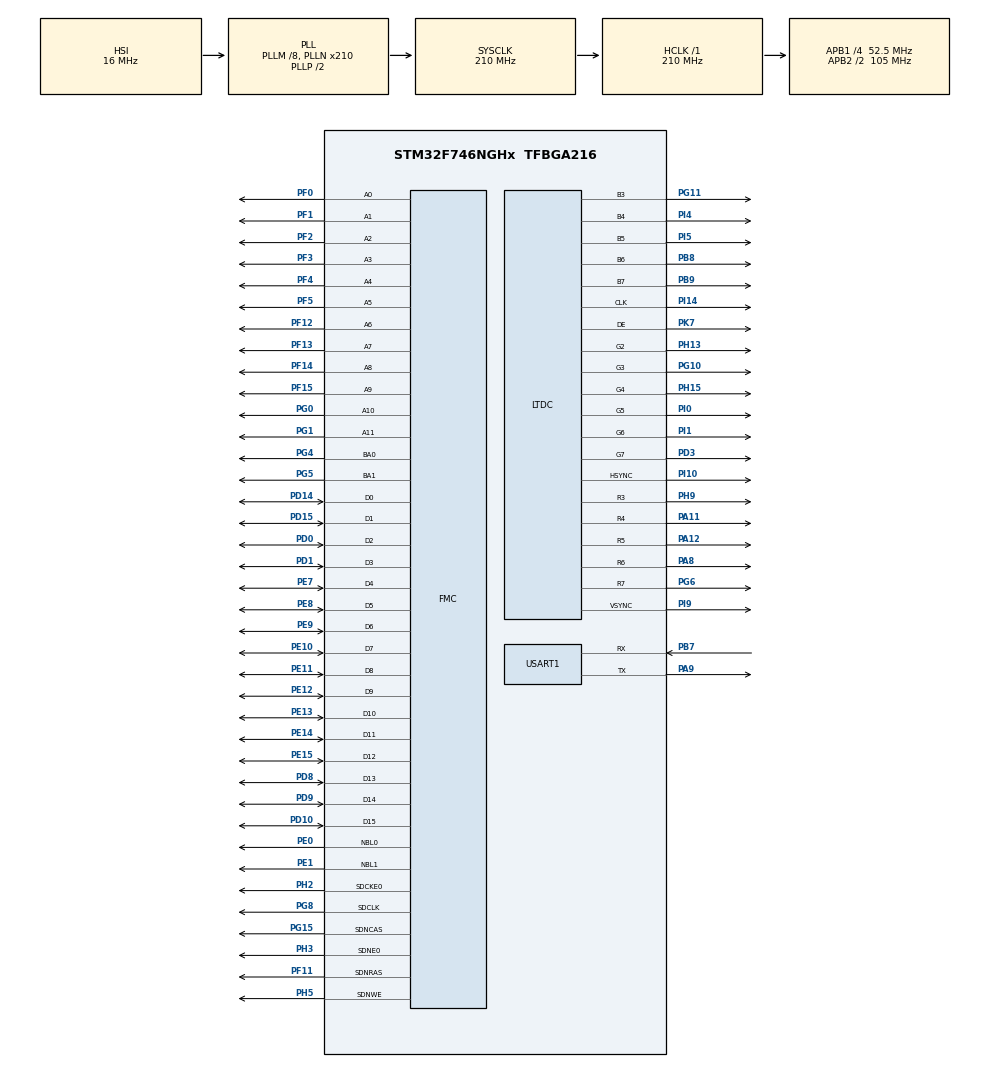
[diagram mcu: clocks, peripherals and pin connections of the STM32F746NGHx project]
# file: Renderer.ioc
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DMA2D.ColorMode=DMA2D_OUTPUT_RGB565
LTDC.Layers=0
LTDC.PixelFormat_L0=LTDC_PIXEL_FORMAT_RGB565
Mcu.Family=STM32F7
Mcu.Name=STM32F746NGHx
Mcu.Package=TFBGA216
NVIC.DMA2D_IRQn=true\:0\:0\:false\:false\:true\:true\:true\:true
NVIC.LTDC_IRQn=true\:0\:0\:false\:false\:true\:true\:true\:true
NVIC.PriorityGroup=NVIC_PRIORITYGROUP_4
PA11.Mode=RGB565
PA11.Signal=LTDC_R4
PA12.Mode=RGB565
PA12.Signal=LTDC_R5
PA13.Mode=Serial_Wire
PA13.Signal=SYS_JTMS-SWDIO
PA14.Mode=Serial_Wire
PA14.Signal=SYS_JTCK-SWCLK
PA8.Mode=RGB565
PA8.Signal=LTDC_R6
PA9.Mode=Asynchronous
PA9.Signal=USART1_TX
PB7.Mode=Asynchronous
PB7.Signal=USART1_RX
PB8.Mode=RGB565
PB8.Signal=LTDC_B6
PB9.Mode=RGB565
PB9.Signal=LTDC_B7
PC14/OSC32_IN.Mode=LSE-External-Oscillator
PC14/OSC32_IN.Signal=RCC_OSC32_IN
PC15/OSC32_OUT.Mode=LSE-External-Oscillator
PC15/OSC32_OUT.Signal=RCC_OSC32_OUT
PD0.Signal=FMC_D2_DA2
PD1.Signal=FMC_D3_DA3
PD10.Signal=FMC_D15_DA15
PD14.Signal=FMC_D0_DA0
PD15.Signal=FMC_D1_DA1
PD3.Mode=RGB565
PD3.Signal=LTDC_G7
PD8.Signal=FMC_D13_DA13
PD9.Signal=FMC_D14_DA14
PE0.Signal=FMC_NBL0
PE1.Signal=FMC_NBL1
PE10.Signal=FMC_D7_DA7
PE11.Signal=FMC_D8_DA8
PE12.Signal=FMC_D9_DA9
PE13.Signal=FMC_D10_DA10
PE14.Signal=FMC_D11_DA11
PE15.Signal=FMC_D12_DA12
PE7.Signal=FMC_D4_DA4
PE8.Signal=FMC_D5_DA5
PE9.Signal=FMC_D6_DA6
PF0.Signal=FMC_A0
PF1.Signal=FMC_A1
PF11.Signal=FMC_SDNRAS
PF12.Signal=FMC_A6
PF13.Signal=FMC_A7
PF14.Signal=FMC_A8
PF15.Signal=FMC_A9
PF2.Signal=FMC_A2
PF3.Signal=FMC_A3
PF4.Signal=FMC_A4
PF5.Signal=FMC_A5
PG0.Signal=FMC_A10
PG1.Signal=FMC_A11
PG10.Mode=RGB565
PG10.Signal=LTDC_G3
PG11.Mode=RGB565
PG11.Signal=LTDC_B3
PG15.Signal=FMC_SDNCAS
PG4.Signal=FMC_A14_BA0
PG5.Signal=FMC_A15_BA1
PG6.Mode=RGB565
PG6.Signal=LTDC_R7
PG8.Signal=FMC_SDCLK
PH0/OSC_IN.Mode=HSE-External-Oscillator
PH0/OSC_IN.Signal=RCC_OSC_IN
PH1/OSC_OUT.Mode=HSE-External-Oscillator
PH1/OSC_OUT.Signal=RCC_OSC_OUT
PH13.Mode=RGB565
PH13.Signal=LTDC_G2
PH15.Mode=RGB565
PH15.Signal=LTDC_G4
PH2.Mode=SdramChipSelect1_1
PH2.Signal=FMC_SDCKE0
PH3.Mode=SdramChipSelect1_1
PH3.Signal=FMC_SDNE0
PH5.Signal=FMC_SDNWE
PH9.Mode=RGB565
PH9.Signal=LTDC_R3
PI0.Mode=RGB565
PI0.Signal=LTDC_G5
PI1.Mode=RGB565
PI1.Signal=LTDC_G6
PI10.Mode=RGB565
PI10.Signal=LTDC_HSYNC
PI14.Mode=RGB565
PI14.Signal=LTDC_CLK
PI4.Mode=RGB565
PI4.Signal=LTDC_B4
PI5.Mode=RGB565
PI5.Signal=LTDC_B5
PI9.Mode=RGB565
PI9.Signal=LTDC_VSYNC
PK7.Mode=RGB565
PK7.Signal=LTDC_DE
ProjectManager.HeapSize=0x200
ProjectManager.StackSize=0x400
ProjectManager.TargetToolchain=CMake
RCC.AHBFreq_Value=210000000
RCC.APB1CLKDivider=RCC_HCLK_DIV4
RCC.APB1Freq_Value=52500000
RCC.APB1TimFreq_Value=105000000
RCC.APB2CLKDivider=RCC_HCLK_DIV2
RCC.APB2Freq_Value=105000000
RCC.APB2TimFreq_Value=210000000
RCC.CortexFreq_Value=210000000
RCC.HCLKFreq_Value=210000000
RCC.HSE_VALUE=25000000
RCC.HSI_VALUE=16000000
RCC.PLLM=8
RCC.PLLN=210
RCC.PLLSAIN=50
RCC.PLLSourceVirtual=RCC_PLLSOURCE_HSI
RCC.SYSCLKFreq_VALUE=210000000
RCC.SYSCLKSource=RCC_SYSCLKSOURCE_PLLCLK
RCC.USBFreq_Value=210000000
RCC.VCOOutputFreq_Value=420000000
SH.FMC_A0.0=FMC_A0,12b-sda1
SH.FMC_A1.0=FMC_A1,12b-sda1
SH.FMC_A10.0=FMC_A10,12b-sda1
SH.FMC_A11.0=FMC_A11,12b-sda1
SH.FMC_A14_BA0.0=FMC_BA0,FourSdramBanks1
SH.FMC_A15_BA1.0=FMC_BA1,FourSdramBanks1
SH.FMC_A2.0=FMC_A2,12b-sda1
SH.FMC_A3.0=FMC_A3,12b-sda1
SH.FMC_A4.0=FMC_A4,12b-sda1
SH.FMC_A5.0=FMC_A5,12b-sda1
SH.FMC_A6.0=FMC_A6,12b-sda1
SH.FMC_A7.0=FMC_A7,12b-sda1
SH.FMC_A8.0=FMC_A8,12b-sda1
SH.FMC_A9.0=FMC_A9,12b-sda1
SH.FMC_D0_DA0.0=FMC_D0,sd-16b-d1
SH.FMC_D10_DA10.0=FMC_D10,sd-16b-d1
SH.FMC_D11_DA11.0=FMC_D11,sd-16b-d1
SH.FMC_D12_DA12.0=FMC_D12,sd-16b-d1
SH.FMC_D13_DA13.0=FMC_D13,sd-16b-d1
SH.FMC_D14_DA14.0=FMC_D14,sd-16b-d1
SH.FMC_D15_DA15.0=FMC_D15,sd-16b-d1
SH.FMC_D1_DA1.0=FMC_D1,sd-16b-d1
SH.FMC_D2_DA2.0=FMC_D2,sd-16b-d1
SH.FMC_D3_DA3.0=FMC_D3,sd-16b-d1
SH.FMC_D4_DA4.0=FMC_D4,sd-16b-d1
SH.FMC_D5_DA5.0=FMC_D5,sd-16b-d1
SH.FMC_D6_DA6.0=FMC_D6,sd-16b-d1
SH.FMC_D7_DA7.0=FMC_D7,sd-16b-d1
SH.FMC_D8_DA8.0=FMC_D8,sd-16b-d1
SH.FMC_D9_DA9.0=FMC_D9,sd-16b-d1
SH.FMC_NBL0.0=FMC_NBL0,Sd2ByteEnable1
SH.FMC_NBL1.0=FMC_NBL1,Sd2ByteEnable1
SH.FMC_SDCLK.0=FMC_SDCLK,12b-sda1
SH.FMC_SDNCAS.0=FMC_SDNCAS,12b-sda1
SH.FMC_SDNRAS.0=FMC_SDNRAS,12b-sda1
SH.FMC_SDNWE.0=FMC_SDNWE,12b-sda1
USART1.VirtualMode-Asynchronous=VM_ASYNC
VP_DMA2D_VS_DMA2D.Mode=DMA2D_Activate
board=STM32F746G-DISCO

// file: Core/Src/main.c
/* USER CODE BEGIN Header */
/**
  ******************************************************************************
  * @file           : main.c
  * @brief          : Main program body
  ******************************************************************************
  * @attention
  *
  * Copyright (c) 2024 STMicroelectronics.
  * All rights reserved.
  *
  * This software is licensed under terms that can be found in the LICENSE file
  * in the root directory of this software component.
  * If no LICENSE file comes with this software, it is provided AS-IS.
  *
  ******************************************************************************
  */
/* USER CODE END Header */
#include "main.h"
#include "dma2d.h"
#include "ltdc.h"
#include "usart.h"
#include "gpio.h"
#include "fmc.h"

/* USER CODE BEGIN Includes */
/* Enable printf */
#include "uart_printf.h"
#include <stdio.h>
#include "renderer.h"
#include "stm32746g_discovery_ts.h"
#include "engine.h"
/* USER CODE END Includes */

void SystemClock_Config(void);

int main(void)
{

  /* MCU Configuration--------------------------------------------------------*/

  /* Reset of all peripherals, Initializes the Flash interface and the Systick. */
  HAL_Init();

  /* Configure the system clock */
  SystemClock_Config();

  /* Initialize all configured peripherals */
  MX_GPIO_Init();
  MX_DMA2D_Init();
  MX_FMC_Init();
  MX_LTDC_Init();
  MX_USART1_UART_Init();
  /* USER CODE BEGIN 2 */
  UART_Printf_Init(&huart1);
  BSP_TS_Init(MAX_WIDTH, MAX_HEIGHT);
  RENDERER_Init(LTDC_PIXEL_FORMAT_RGB565);
  Engine_Init();
  /* USER CODE END 2 */

  /* Infinite loop */
  /* USER CODE BEGIN WHILE */
  while (1)
  {
    Engine_Collect();
    Engine_Update();
    Engine_Render();
    Engine_Wait();
    /* USER CODE END WHILE */

  }
}

void SystemClock_Config(void)
{
  RCC_OscInitTypeDef RCC_OscInitStruct = {0};
  RCC_ClkInitTypeDef RCC_ClkInitStruct = {0};

  /** Configure LSE Drive Capability
  */
  HAL_PWR_EnableBkUpAccess();

  /** Configure the main internal regulator output voltage
  */
  __HAL_RCC_PWR_CLK_ENABLE();
  __HAL_PWR_VOLTAGESCALING_CONFIG(PWR_REGULATOR_VOLTAGE_SCALE1);

  /** Initializes the RCC Oscillators according to the specified parameters
  * in the RCC_OscInitTypeDef structure.
  */
  RCC_OscInitStruct.OscillatorType = RCC_OSCILLATORTYPE_HSI;
  RCC_OscInitStruct.HSIState = RCC_HSI_ON;
  RCC_OscInitStruct.HSICalibrationValue = RCC_HSICALIBRATION_DEFAULT;
  RCC_OscInitStruct.PLL.PLLState = RCC_PLL_ON;
  RCC_OscInitStruct.PLL.PLLSource = RCC_PLLSOURCE_HSI;
  RCC_OscInitStruct.PLL.PLLM = 8;
  RCC_OscInitStruct.PLL.PLLN = 210;
  RCC_OscInitStruct.PLL.PLLP = RCC_PLLP_DIV2;
  RCC_OscInitStruct.PLL.PLLQ = 2;
  if (HAL_RCC_OscConfig(&RCC_OscInitStruct) != HAL_OK)
  {
    Error_Handler();
  }

  /** Activate the Over-Drive mode
  */
  if (HAL_PWREx_EnableOverDrive() != HAL_OK)
  {
    Error_Handler();
  }

  /** Initializes the CPU, AHB and APB buses clocks
  */
  RCC_ClkInitStruct.ClockType = RCC_CLOCKTYPE_HCLK|RCC_CLOCKTYPE_SYSCLK
                              |RCC_CLOCKTYPE_PCLK1|RCC_CLOCKTYPE_PCLK2;
  RCC_ClkInitStruct.SYSCLKSource = RCC_SYSCLKSOURCE_PLLCLK;
  RCC_ClkInitStruct.AHBCLKDivider = RCC_SYSCLK_DIV1;
  RCC_ClkInitStruct.APB1CLKDivider = RCC_HCLK_DIV4;
  RCC_ClkInitStruct.APB2CLKDivider = RCC_HCLK_DIV2;

  if (HAL_RCC_ClockConfig(&RCC_ClkInitStruct, FLASH_LATENCY_6) != HAL_OK)
  {
    Error_Handler();
  }
}

void Error_Handler(void)
{
  __disable_irq();
  while (1)
  {
  }
}
